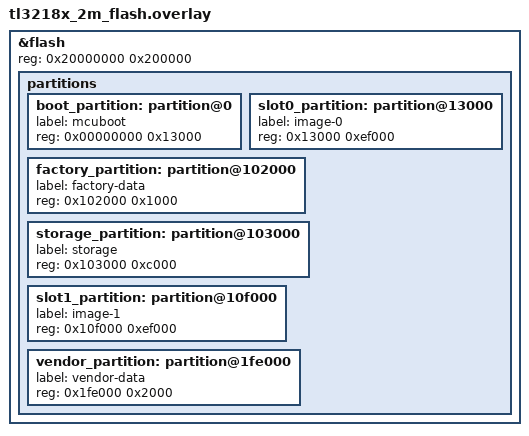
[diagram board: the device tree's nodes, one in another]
&flash {
	reg = <0x20000000 0x200000>;

	partitions {
		/delete-node/ partition@0;
		/delete-node/ partition@20000;
		/delete-node/ partition@88000;
		/delete-node/ partition@f0000;
		/delete-node/ partition@f4000;
		/delete-node/ partition@fe000;
		boot_partition: partition@0 {
			label = "mcuboot";
			reg = <0x00000000 0x13000>;
		};
		slot0_partition: partition@13000 {
			label = "image-0";
			reg = <0x13000 0xef000>;
		};
		factory_partition: partition@102000 {
			label = "factory-data";
			reg = <0x102000 0x1000>;
		};
		storage_partition: partition@103000 {
			label = "storage";
			reg = <0x103000 0xc000>;
		};
		slot1_partition: partition@10f000 {
			label = "image-1";
			reg = <0x10f000 0xef000>;
		};
		vendor_partition: partition@1fe000 {
			label = "vendor-data";
			reg = <0x1fe000 0x2000>;
		};
	};
};
